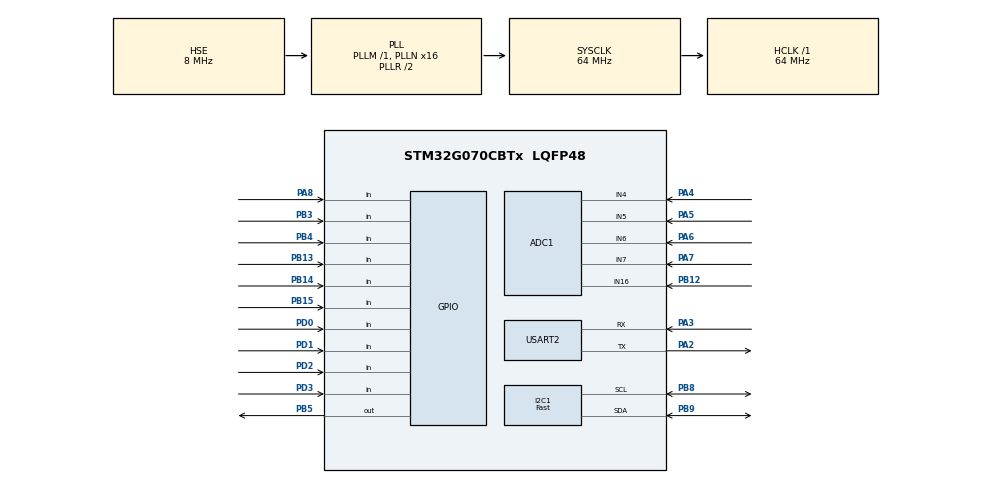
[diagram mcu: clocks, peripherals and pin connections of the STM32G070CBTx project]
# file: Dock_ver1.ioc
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ADC1.DMAContinuousRequests=DISABLE
ADC1.DiscontinuousConvMode=ENABLE
ADC1.EOCSelection=ADC_EOC_SEQ_CONV
ADC1.NbrOfConversion=1
ADC1.NbrOfConversionFlag=0
ADC1.SelectedChannel=ADC_CHANNEL_4|ADC_CHANNEL_5|ADC_CHANNEL_6|ADC_CHANNEL_7|ADC_CHANNEL_16
ADC1.Sequencer=NOT_FULLY_CONFIGURABLE
ADC1.master=1
Dma.ADC1.0.Direction=DMA_PERIPH_TO_MEMORY
Dma.ADC1.0.EventEnable=DISABLE
Dma.ADC1.0.Instance=DMA1_Channel1
Dma.ADC1.0.MemDataAlignment=DMA_MDATAALIGN_WORD
Dma.ADC1.0.MemInc=DMA_MINC_ENABLE
Dma.ADC1.0.Mode=DMA_CIRCULAR
Dma.ADC1.0.PeriphDataAlignment=DMA_PDATAALIGN_WORD
Dma.ADC1.0.PeriphInc=DMA_PINC_DISABLE
Dma.ADC1.0.Polarity=HAL_DMAMUX_REQ_GEN_RISING
Dma.ADC1.0.Priority=DMA_PRIORITY_LOW
Dma.ADC1.0.RequestNumber=1
Dma.ADC1.0.SignalID=NONE
Dma.ADC1.0.SyncEnable=DISABLE
Dma.ADC1.0.SyncPolarity=HAL_DMAMUX_SYNC_NO_EVENT
Dma.ADC1.0.SyncRequestNumber=1
Dma.ADC1.0.SyncSignalID=NONE
Dma.Request0=ADC1
I2C1.I2C_Speed_Mode=I2C_Fast
I2C1.Timing=0x00602173
Mcu.Family=STM32G0
Mcu.Name=STM32G070CBTx
Mcu.Package=LQFP48
NVIC.DMA1_Channel1_IRQn=true\:0\:0\:false\:false\:true\:false\:true\:true
PA13.Mode=Serial_Wire
PA13.Signal=SYS_SWDIO
PA14-BOOT0.Mode=Serial_Wire
PA14-BOOT0.Signal=SYS_SWCLK
PA2.Mode=Asynchronous
PA2.Signal=USART2_TX
PA3.Mode=Asynchronous
PA3.Signal=USART2_RX
PA4.Mode=IN4
PA4.Signal=ADC1_IN4
PA5.Mode=IN5
PA5.Signal=ADC1_IN5
PA6.Mode=IN6
PA6.Signal=ADC1_IN6
PA7.Mode=IN7
PA7.Signal=ADC1_IN7
PA8.Signal=GPIO_Input
PB12.Mode=IN16
PB12.Signal=ADC1_IN16
PB13.Signal=GPIO_Input
PB14.Signal=GPIO_Input
PB15.Signal=GPIO_Input
PB3.GPIO_PuPd=GPIO_PULLUP
PB3.Signal=GPIO_Input
PB4.GPIO_PuPd=GPIO_PULLUP
PB4.Signal=GPIO_Input
PB5.Signal=GPIO_Output
PB8.Mode=I2C
PB8.Signal=I2C1_SCL
PB9.Mode=I2C
PB9.Signal=I2C1_SDA
PD0.Signal=GPIO_Input
PD1.GPIO_PuPd=GPIO_PULLUP
PD1.Signal=GPIO_Input
PD2.GPIO_PuPd=GPIO_PULLUP
PD2.Signal=GPIO_Input
PD3.GPIO_PuPd=GPIO_PULLUP
PD3.Signal=GPIO_Input
PF0-OSC_IN\ (PF0).Mode=HSE-External-Oscillator
PF0-OSC_IN\ (PF0).Signal=RCC_OSC_IN
PF1-OSC_OUT\ (PF1).Mode=HSE-External-Oscillator
PF1-OSC_OUT\ (PF1).Signal=RCC_OSC_OUT
ProjectManager.HeapSize=0x200
ProjectManager.StackSize=0x400
ProjectManager.TargetToolchain=STM32CubeIDE
RCC.ADCFreq_Value=64000000
RCC.AHBFreq_Value=64000000
RCC.CortexFreq_Value=64000000
RCC.EXTERNAL_CLOCK_VALUE=48000
RCC.HCLKFreq_Value=64000000
RCC.HSE_VALUE=8000000
RCC.HSI_VALUE=16000000
RCC.LSE_VALUE=32768
RCC.PLLN=16
RCC.PLLSourceVirtual=RCC_PLLSOURCE_HSE
RCC.SYSCLKFreq_VALUE=64000000
RCC.SYSCLKSource=RCC_SYSCLKSOURCE_PLLCLK
RCC.VCOOutputFreq_Value=128000000
USART2.VirtualMode-Asynchronous=VM_ASYNC
VP_SYS_VS_DBSignals.Mode=DisableDeadBatterySignals
board=custom

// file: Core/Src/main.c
/* USER CODE BEGIN Header */
/**
  ******************************************************************************
  * @file           : main.c
  * @brief          : Main program body
  ******************************************************************************
  * @attention
  *
  * Copyright (c) 2024 STMicroelectronics.
  * All rights reserved.
  *
  * This software is licensed under terms that can be found in the LICENSE file
  * in the root directory of this software component.
  * If no LICENSE file comes with this software, it is provided AS-IS.
  *
  ******************************************************************************
  */
/* USER CODE END Header */
#include "main.h"

/* USER CODE BEGIN Includes */
#include <stdio.h>
#include "ssd1306.h"

/* USER CODE END Includes */

/* USER CODE BEGIN PD */

//calibration for ADC channels(nominal 244141)
#define ICAL_CH1 244141
#define ICAL_CH2 244141
#define ICAL_CH3 244141
#define ICAL_CH4 244141
#define ICAL_CH5 249042

/* USER CODE END PD */

ADC_HandleTypeDef hadc1;
DMA_HandleTypeDef hdma_adc1;

I2C_HandleTypeDef hi2c1;

UART_HandleTypeDef huart2;

void SystemClock_Config(void);
static void MX_GPIO_Init(void);
static void MX_DMA_Init(void);
static void MX_ADC1_Init(void);
static void MX_I2C1_Init(void);
static void MX_USART2_UART_Init(void);

/* USER CODE BEGIN 0 */
uint32_t AD_RES_BUFFER[5];

/* USER CODE END 0 */

int main(void)
{

  /* MCU Configuration--------------------------------------------------------*/

  /* Reset of all peripherals, Initializes the Flash interface and the Systick. */
  HAL_Init();

  /* Configure the system clock */
  SystemClock_Config();

  /* Initialize all configured peripherals */
  MX_GPIO_Init();
  MX_DMA_Init();
  MX_ADC1_Init();
  MX_I2C1_Init();
  MX_USART2_UART_Init();
  /* USER CODE BEGIN 2 */

  HAL_ADCEx_Calibration_Start(&hadc1);

  /* USER CODE END 2 */

  /* Infinite loop */
  /* USER CODE BEGIN WHILE */
  ssd1306_Init();

  while(1){
  // Start ADC Conversion in DMA Mode (Periodically Every 1ms)
  HAL_ADC_Start_DMA(&hadc1, AD_RES_BUFFER, 5);
  //ssd1306_TestBorder();
  //ssd1306_TestAll();
  HAL_Delay(100);
  }

//  while (1)
//  {
//    /* USER CODE END WHILE */
//
//    /* USER CODE BEGIN 3 */
//	  uint8_t str[100], port1_pres, port2_pres, port3_pres, port4_pres, port5_pres;
//	  uint32_t value_adc, value_current;
//	  uint16_t str_len;
//
//	  port1_pres = HAL_GPIO_ReadPin(GPIOA, GPIO_PIN_8);
//	  port2_pres = HAL_GPIO_ReadPin(GPIOB, GPIO_PIN_14);
//	  port3_pres = HAL_GPIO_ReadPin(GPIOB, GPIO_PIN_13);
//	  port4_pres = HAL_GPIO_ReadPin(GPIOB, GPIO_PIN_15);
//	  port5_pres = HAL_GPIO_ReadPin(GPIOD, GPIO_PIN_0);
//
//	  HAL_ADC_Start(&hadc1);
//	  value_adc = HAL_ADC_GetValue(&hadc1);
//	  value_current = (value_adc*ICAL_CH5)/1000000;
//
//	  str_len = sprintf(str, "ADC:%ld I:%ld\n\r1:%d 2:%d 3:%d 4:%d 5:%d\n\n\r", value_adc, value_current, port1_pres, port2_pres, port3_pres, port4_pres, port5_pres);
//	  HAL_UART_Transmit(&huart2, str, str_len, 100);
//	  HAL_Delay(250);
//  }
  /* USER CODE END 3 */
}

void SystemClock_Config(void)
{
  RCC_OscInitTypeDef RCC_OscInitStruct = {0};
  RCC_ClkInitTypeDef RCC_ClkInitStruct = {0};

  /** Configure the main internal regulator output voltage
  */
  HAL_PWREx_ControlVoltageScaling(PWR_REGULATOR_VOLTAGE_SCALE1);

  /** Initializes the RCC Oscillators according to the specified parameters
  * in the RCC_OscInitTypeDef structure.
  */
  RCC_OscInitStruct.OscillatorType = RCC_OSCILLATORTYPE_HSE;
  RCC_OscInitStruct.HSEState = RCC_HSE_ON;
  RCC_OscInitStruct.PLL.PLLState = RCC_PLL_ON;
  RCC_OscInitStruct.PLL.PLLSource = RCC_PLLSOURCE_HSE;
  RCC_OscInitStruct.PLL.PLLM = RCC_PLLM_DIV1;
  RCC_OscInitStruct.PLL.PLLN = 16;
  RCC_OscInitStruct.PLL.PLLP = RCC_PLLP_DIV2;
  RCC_OscInitStruct.PLL.PLLR = RCC_PLLR_DIV2;
  if (HAL_RCC_OscConfig(&RCC_OscInitStruct) != HAL_OK)
  {
    Error_Handler();
  }

  /** Initializes the CPU, AHB and APB buses clocks
  */
  RCC_ClkInitStruct.ClockType = RCC_CLOCKTYPE_HCLK|RCC_CLOCKTYPE_SYSCLK
                              |RCC_CLOCKTYPE_PCLK1;
  RCC_ClkInitStruct.SYSCLKSource = RCC_SYSCLKSOURCE_PLLCLK;
  RCC_ClkInitStruct.AHBCLKDivider = RCC_SYSCLK_DIV1;
  RCC_ClkInitStruct.APB1CLKDivider = RCC_HCLK_DIV1;

  if (HAL_RCC_ClockConfig(&RCC_ClkInitStruct, FLASH_LATENCY_2) != HAL_OK)
  {
    Error_Handler();
  }
}

void HAL_ADC_ConvCpltCallback(ADC_HandleTypeDef* hadc)
{
	uint8_t str[100], str_oled[100];
	uint32_t value_current[5];
	uint16_t str_len, value_current_tot;

	value_current_tot = 0;
	for(uint8_t i=0;i<5;i++){
	value_current[i] = (AD_RES_BUFFER[i]*ICAL_CH5)/1000000; //need to add individual channel calibration values
	value_current_tot += value_current[i];
	}

	str_len = sprintf(str, "1:%ldma 2:%ldma 3:%ldma 4:%ldma 5:%ldma\n\rtotal:%dma\n\n\r", value_current[4], value_current[3], value_current[2], value_current[1], value_current[0], value_current_tot);
	HAL_UART_Transmit(&huart2, str, str_len, 100);

	sprintf(str_oled, "1:%ldma 2:%ldma 3:%ldma      ", value_current[4], value_current[3], value_current[2]);
    ssd1306_SetCursor(0,0);
    ssd1306_WriteString(str_oled, Font_6x8, White);
	sprintf(str_oled, "4:%ldma 5:%ldma T:%dma      ", value_current[1], value_current[0], value_current_tot);
    ssd1306_SetCursor(0,10);
    ssd1306_WriteString(str_oled, Font_6x8, White);
    ssd1306_UpdateScreen();
}

static void MX_ADC1_Init(void)
{

  ADC_ChannelConfTypeDef sConfig = {0};

  /** Configure the global features of the ADC (Clock, Resolution, Data Alignment and number of conversion)
  */
  hadc1.Instance = ADC1;
  hadc1.Init.ClockPrescaler = ADC_CLOCK_SYNC_PCLK_DIV2;
  hadc1.Init.Resolution = ADC_RESOLUTION_12B;
  hadc1.Init.DataAlign = ADC_DATAALIGN_RIGHT;
  hadc1.Init.ScanConvMode = ADC_SCAN_SEQ_FIXED;
  hadc1.Init.EOCSelection = ADC_EOC_SEQ_CONV;
  hadc1.Init.LowPowerAutoWait = DISABLE;
  hadc1.Init.LowPowerAutoPowerOff = DISABLE;
  hadc1.Init.ContinuousConvMode = DISABLE;
  hadc1.Init.NbrOfConversion = 1;
  hadc1.Init.DiscontinuousConvMode = ENABLE;
  hadc1.Init.ExternalTrigConv = ADC_SOFTWARE_START;
  hadc1.Init.ExternalTrigConvEdge = ADC_EXTERNALTRIGCONVEDGE_NONE;
  hadc1.Init.DMAContinuousRequests = DISABLE;
  hadc1.Init.Overrun = ADC_OVR_DATA_PRESERVED;
  hadc1.Init.SamplingTimeCommon1 = ADC_SAMPLETIME_1CYCLE_5;
  hadc1.Init.OversamplingMode = DISABLE;
  hadc1.Init.TriggerFrequencyMode = ADC_TRIGGER_FREQ_HIGH;
  if (HAL_ADC_Init(&hadc1) != HAL_OK)
  {
    Error_Handler();
  }

  /** Configure Regular Channel
  */
  sConfig.Channel = ADC_CHANNEL_4;
  sConfig.Rank = ADC_RANK_CHANNEL_NUMBER;
  if (HAL_ADC_ConfigChannel(&hadc1, &sConfig) != HAL_OK)
  {
    Error_Handler();
  }

  /** Configure Regular Channel
  */
  sConfig.Channel = ADC_CHANNEL_5;
  if (HAL_ADC_ConfigChannel(&hadc1, &sConfig) != HAL_OK)
  {
    Error_Handler();
  }

  /** Configure Regular Channel
  */
  sConfig.Channel = ADC_CHANNEL_6;
  if (HAL_ADC_ConfigChannel(&hadc1, &sConfig) != HAL_OK)
  {
    Error_Handler();
  }

  /** Configure Regular Channel
  */
  sConfig.Channel = ADC_CHANNEL_7;
  if (HAL_ADC_ConfigChannel(&hadc1, &sConfig) != HAL_OK)
  {
    Error_Handler();
  }

  /** Configure Regular Channel
  */
  sConfig.Channel = ADC_CHANNEL_16;
  if (HAL_ADC_ConfigChannel(&hadc1, &sConfig) != HAL_OK)
  {
    Error_Handler();
  }

}

static void MX_I2C1_Init(void)
{

  hi2c1.Instance = I2C1;
  hi2c1.Init.Timing = 0x00602173;
  hi2c1.Init.OwnAddress1 = 0;
  hi2c1.Init.AddressingMode = I2C_ADDRESSINGMODE_7BIT;
  hi2c1.Init.DualAddressMode = I2C_DUALADDRESS_DISABLE;
  hi2c1.Init.OwnAddress2 = 0;
  hi2c1.Init.OwnAddress2Masks = I2C_OA2_NOMASK;
  hi2c1.Init.GeneralCallMode = I2C_GENERALCALL_DISABLE;
  hi2c1.Init.NoStretchMode = I2C_NOSTRETCH_DISABLE;
  if (HAL_I2C_Init(&hi2c1) != HAL_OK)
  {
    Error_Handler();
  }

  /** Configure Analogue filter
  */
  if (HAL_I2CEx_ConfigAnalogFilter(&hi2c1, I2C_ANALOGFILTER_ENABLE) != HAL_OK)
  {
    Error_Handler();
  }

  /** Configure Digital filter
  */
  if (HAL_I2CEx_ConfigDigitalFilter(&hi2c1, 0) != HAL_OK)
  {
    Error_Handler();
  }

}

static void MX_USART2_UART_Init(void)
{

  huart2.Instance = USART2;
  huart2.Init.BaudRate = 115200;
  huart2.Init.WordLength = UART_WORDLENGTH_8B;
  huart2.Init.StopBits = UART_STOPBITS_1;
  huart2.Init.Parity = UART_PARITY_NONE;
  huart2.Init.Mode = UART_MODE_TX_RX;
  huart2.Init.HwFlowCtl = UART_HWCONTROL_NONE;
  huart2.Init.OverSampling = UART_OVERSAMPLING_16;
  huart2.Init.OneBitSampling = UART_ONE_BIT_SAMPLE_DISABLE;
  huart2.Init.ClockPrescaler = UART_PRESCALER_DIV1;
  huart2.AdvancedInit.AdvFeatureInit = UART_ADVFEATURE_NO_INIT;
  if (HAL_UART_Init(&huart2) != HAL_OK)
  {
    Error_Handler();
  }
  if (HAL_UARTEx_SetTxFifoThreshold(&huart2, UART_TXFIFO_THRESHOLD_1_8) != HAL_OK)
  {
    Error_Handler();
  }
  if (HAL_UARTEx_SetRxFifoThreshold(&huart2, UART_RXFIFO_THRESHOLD_1_8) != HAL_OK)
  {
    Error_Handler();
  }
  if (HAL_UARTEx_DisableFifoMode(&huart2) != HAL_OK)
  {
    Error_Handler();
  }

}

static void MX_DMA_Init(void)
{

  /* DMA controller clock enable */
  __HAL_RCC_DMA1_CLK_ENABLE();

  /* DMA interrupt init */
  /* DMA1_Channel1_IRQn interrupt configuration */
  HAL_NVIC_SetPriority(DMA1_Channel1_IRQn, 0, 0);
  HAL_NVIC_EnableIRQ(DMA1_Channel1_IRQn);

}

static void MX_GPIO_Init(void)
{
  GPIO_InitTypeDef GPIO_InitStruct = {0};

  /* GPIO Ports Clock Enable */
  __HAL_RCC_GPIOF_CLK_ENABLE();
  __HAL_RCC_GPIOA_CLK_ENABLE();
  __HAL_RCC_GPIOB_CLK_ENABLE();
  __HAL_RCC_GPIOD_CLK_ENABLE();

  /*Configure GPIO pin Output Level */
  HAL_GPIO_WritePin(GPIOB, GPIO_PIN_5, GPIO_PIN_RESET);

  /*Configure GPIO pins : PB13 PB14 PB15 */
  GPIO_InitStruct.Pin = GPIO_PIN_13|GPIO_PIN_14|GPIO_PIN_15;
  GPIO_InitStruct.Mode = GPIO_MODE_INPUT;
  GPIO_InitStruct.Pull = GPIO_NOPULL;
  HAL_GPIO_Init(GPIOB, &GPIO_InitStruct);

  /*Configure GPIO pin : PA8 */
  GPIO_InitStruct.Pin = GPIO_PIN_8;
  GPIO_InitStruct.Mode = GPIO_MODE_INPUT;
  GPIO_InitStruct.Pull = GPIO_NOPULL;
  HAL_GPIO_Init(GPIOA, &GPIO_InitStruct);

  /*Configure GPIO pin : PD0 */
  GPIO_InitStruct.Pin = GPIO_PIN_0;
  GPIO_InitStruct.Mode = GPIO_MODE_INPUT;
  GPIO_InitStruct.Pull = GPIO_NOPULL;
  HAL_GPIO_Init(GPIOD, &GPIO_InitStruct);

  /*Configure GPIO pins : PD1 PD2 PD3 */
  GPIO_InitStruct.Pin = GPIO_PIN_1|GPIO_PIN_2|GPIO_PIN_3;
  GPIO_InitStruct.Mode = GPIO_MODE_INPUT;
  GPIO_InitStruct.Pull = GPIO_PULLUP;
  HAL_GPIO_Init(GPIOD, &GPIO_InitStruct);

  /*Configure GPIO pins : PB3 PB4 */
  GPIO_InitStruct.Pin = GPIO_PIN_3|GPIO_PIN_4;
  GPIO_InitStruct.Mode = GPIO_MODE_INPUT;
  GPIO_InitStruct.Pull = GPIO_PULLUP;
  HAL_GPIO_Init(GPIOB, &GPIO_InitStruct);

  /*Configure GPIO pin : PB5 */
  GPIO_InitStruct.Pin = GPIO_PIN_5;
  GPIO_InitStruct.Mode = GPIO_MODE_OUTPUT_PP;
  GPIO_InitStruct.Pull = GPIO_NOPULL;
  GPIO_InitStruct.Speed = GPIO_SPEED_FREQ_LOW;
  HAL_GPIO_Init(GPIOB, &GPIO_InitStruct);

}

void Error_Handler(void)
{
  __disable_irq();
  while (1)
  {
  }
}
